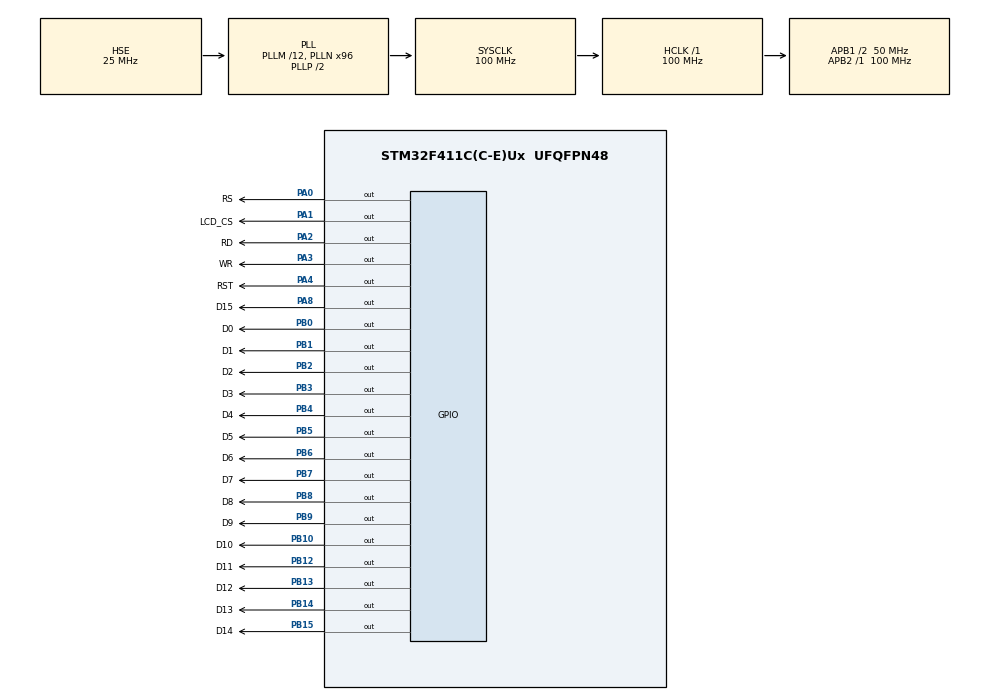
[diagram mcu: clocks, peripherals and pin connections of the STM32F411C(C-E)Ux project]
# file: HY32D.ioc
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Mcu.Family=STM32F4
Mcu.Name=STM32F411C(C-E)Ux
Mcu.Package=UFQFPN48
NVIC.PriorityGroup=NVIC_PRIORITYGROUP_4
PA0-WKUP.GPIO_Label=RS
PA0-WKUP.GPIO_Speed=GPIO_SPEED_FREQ_MEDIUM
PA0-WKUP.Signal=GPIO_Output
PA1.GPIO_Label=LCD_CS
PA1.GPIO_Speed=GPIO_SPEED_FREQ_MEDIUM
PA1.Signal=GPIO_Output
PA13.Mode=Serial_Wire
PA13.Signal=SYS_JTMS-SWDIO
PA14.Mode=Serial_Wire
PA14.Signal=SYS_JTCK-SWCLK
PA2.GPIO_Label=RD
PA2.GPIO_Speed=GPIO_SPEED_FREQ_MEDIUM
PA2.Signal=GPIO_Output
PA3.GPIO_Label=WR
PA3.GPIO_Speed=GPIO_SPEED_FREQ_MEDIUM
PA3.Signal=GPIO_Output
PA4.GPIO_Label=RST
PA4.GPIO_Speed=GPIO_SPEED_FREQ_MEDIUM
PA4.Signal=GPIO_Output
PA8.GPIO_Label=D15
PA8.GPIO_Speed=GPIO_SPEED_FREQ_MEDIUM
PA8.Signal=GPIO_Output
PB0.GPIO_Label=D0
PB0.GPIO_Speed=GPIO_SPEED_FREQ_MEDIUM
PB0.Signal=GPIO_Output
PB1.GPIO_Label=D1
PB1.GPIO_Speed=GPIO_SPEED_FREQ_MEDIUM
PB1.Signal=GPIO_Output
PB10.GPIO_Label=D10
PB10.GPIO_Speed=GPIO_SPEED_FREQ_MEDIUM
PB10.Signal=GPIO_Output
PB12.GPIO_Label=D11
PB12.GPIO_Speed=GPIO_SPEED_FREQ_MEDIUM
PB12.Signal=GPIO_Output
PB13.GPIO_Label=D12
PB13.GPIO_Speed=GPIO_SPEED_FREQ_MEDIUM
PB13.Signal=GPIO_Output
PB14.GPIO_Label=D13
PB14.GPIO_Speed=GPIO_SPEED_FREQ_MEDIUM
PB14.Signal=GPIO_Output
PB15.GPIO_Label=D14
PB15.GPIO_Speed=GPIO_SPEED_FREQ_MEDIUM
PB15.Signal=GPIO_Output
PB2.GPIO_Label=D2
PB2.GPIO_Speed=GPIO_SPEED_FREQ_MEDIUM
PB2.Signal=GPIO_Output
PB3.GPIO_Label=D3
PB3.GPIO_Speed=GPIO_SPEED_FREQ_MEDIUM
PB3.Signal=GPIO_Output
PB4.GPIO_Label=D4
PB4.GPIO_Speed=GPIO_SPEED_FREQ_MEDIUM
PB4.Signal=GPIO_Output
PB5.GPIO_Label=D5
PB5.GPIO_Speed=GPIO_SPEED_FREQ_MEDIUM
PB5.Signal=GPIO_Output
PB6.GPIO_Label=D6
PB6.GPIO_Speed=GPIO_SPEED_FREQ_MEDIUM
PB6.Signal=GPIO_Output
PB7.GPIO_Label=D7
PB7.GPIO_Speed=GPIO_SPEED_FREQ_MEDIUM
PB7.Signal=GPIO_Output
PB8.GPIO_Label=D8
PB8.GPIO_Speed=GPIO_SPEED_FREQ_MEDIUM
PB8.Signal=GPIO_Output
PB9.GPIO_Label=D9
PB9.GPIO_Speed=GPIO_SPEED_FREQ_MEDIUM
PB9.Signal=GPIO_Output
PH0\ -\ OSC_IN.Mode=HSE-External-Oscillator
PH0\ -\ OSC_IN.Signal=RCC_OSC_IN
PH1\ -\ OSC_OUT.Mode=HSE-External-Oscillator
PH1\ -\ OSC_OUT.Signal=RCC_OSC_OUT
ProjectManager.HeapSize=0x200
ProjectManager.StackSize=0x400
ProjectManager.TargetToolchain=EWARM V8
RCC.48MHZClocksFreq_Value=50000000
RCC.AHBFreq_Value=100000000
RCC.APB1CLKDivider=RCC_HCLK_DIV2
RCC.APB1Freq_Value=50000000
RCC.APB1TimFreq_Value=100000000
RCC.APB2Freq_Value=100000000
RCC.APB2TimFreq_Value=100000000
RCC.CortexFreq_Value=100000000
RCC.EnbaleCSS=true
RCC.HCLKFreq_Value=100000000
RCC.HSE_VALUE=25000000
RCC.HSI_VALUE=16000000
RCC.LSE_VALUE=32768
RCC.PLLM=12
RCC.PLLN=96
RCC.PLLSourceVirtual=RCC_PLLSOURCE_HSE
RCC.SYSCLKFreq_VALUE=100000000
RCC.SYSCLKSource=RCC_SYSCLKSOURCE_PLLCLK
RCC.VCOOutputFreq_Value=200000000
board=custom

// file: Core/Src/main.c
/* USER CODE BEGIN Header */
/**
  ******************************************************************************
  * @file           : main.c
  * @brief          : Main program body
  ******************************************************************************
  * @attention
  *
  * Copyright (c) 2023 STMicroelectronics.
  * All rights reserved.
  *
  * This software is licensed under terms that can be found in the LICENSE file
  * in the root directory of this software component.
  * If no LICENSE file comes with this software, it is provided AS-IS.
  *
  ******************************************************************************
  */
/* USER CODE END Header */
#include "main.h"

void SystemClock_Config(void);
static void MX_GPIO_Init(void);
/* USER CODE BEGIN PFP */
void HY32D_Init()
{
  GPIOA->ODR = (1<<RD_Pin);
  GPIOB->ODR = 0x07;
  GPIOA->ODR = (1<<WR_Pin);
  GPIOB->ODR = 0x21;

}
/* USER CODE END PFP */

int main(void)
{

  /* MCU Configuration--------------------------------------------------------*/

  /* Reset of all peripherals, Initializes the Flash interface and the Systick. */
  HAL_Init();

  /* Configure the system clock */
  SystemClock_Config();

  /* Initialize all configured peripherals */
  MX_GPIO_Init();

  /* Infinite loop */
  while (1)
  {

  }
}

void SystemClock_Config(void)
{
  RCC_OscInitTypeDef RCC_OscInitStruct = {0};
  RCC_ClkInitTypeDef RCC_ClkInitStruct = {0};

  /** Configure the main internal regulator output voltage
  */
  __HAL_RCC_PWR_CLK_ENABLE();
  __HAL_PWR_VOLTAGESCALING_CONFIG(PWR_REGULATOR_VOLTAGE_SCALE1);

  /** Initializes the RCC Oscillators according to the specified parameters
  * in the RCC_OscInitTypeDef structure.
  */
  RCC_OscInitStruct.OscillatorType = RCC_OSCILLATORTYPE_HSE;
  RCC_OscInitStruct.HSEState = RCC_HSE_ON;
  RCC_OscInitStruct.PLL.PLLState = RCC_PLL_ON;
  RCC_OscInitStruct.PLL.PLLSource = RCC_PLLSOURCE_HSE;
  RCC_OscInitStruct.PLL.PLLM = 12;
  RCC_OscInitStruct.PLL.PLLN = 96;
  RCC_OscInitStruct.PLL.PLLP = RCC_PLLP_DIV2;
  RCC_OscInitStruct.PLL.PLLQ = 4;
  if (HAL_RCC_OscConfig(&RCC_OscInitStruct) != HAL_OK)
  {
    Error_Handler();
  }

  /** Initializes the CPU, AHB and APB buses clocks
  */
  RCC_ClkInitStruct.ClockType = RCC_CLOCKTYPE_HCLK|RCC_CLOCKTYPE_SYSCLK
                              |RCC_CLOCKTYPE_PCLK1|RCC_CLOCKTYPE_PCLK2;
  RCC_ClkInitStruct.SYSCLKSource = RCC_SYSCLKSOURCE_PLLCLK;
  RCC_ClkInitStruct.AHBCLKDivider = RCC_SYSCLK_DIV1;
  RCC_ClkInitStruct.APB1CLKDivider = RCC_HCLK_DIV2;
  RCC_ClkInitStruct.APB2CLKDivider = RCC_HCLK_DIV1;

  if (HAL_RCC_ClockConfig(&RCC_ClkInitStruct, FLASH_LATENCY_3) != HAL_OK)
  {
    Error_Handler();
  }

  /** Enables the Clock Security System
  */
  HAL_RCC_EnableCSS();
}

static void MX_GPIO_Init(void)
{
  GPIO_InitTypeDef GPIO_InitStruct = {0};

  /* GPIO Ports Clock Enable */
  __HAL_RCC_GPIOH_CLK_ENABLE();
  __HAL_RCC_GPIOA_CLK_ENABLE();
  __HAL_RCC_GPIOB_CLK_ENABLE();

  /*Configure GPIO pin Output Level */
  HAL_GPIO_WritePin(GPIOA, RS_Pin|LCD_CS_Pin|RD_Pin|WR_Pin
                          |RST_Pin|D15_Pin, GPIO_PIN_RESET);

  /*Configure GPIO pin Output Level */
  HAL_GPIO_WritePin(GPIOB, D0_Pin|D1_Pin|D2_Pin|D10_Pin
                          |D11_Pin|D12_Pin|D13_Pin|D14_Pin
                          |D3_Pin|D4_Pin|D5_Pin|D6_Pin
                          |D7_Pin|D8_Pin|D9_Pin, GPIO_PIN_RESET);

  /*Configure GPIO pins : RS_Pin LCD_CS_Pin RD_Pin WR_Pin
                           RST_Pin D15_Pin */
  GPIO_InitStruct.Pin = RS_Pin|LCD_CS_Pin|RD_Pin|WR_Pin
                          |RST_Pin|D15_Pin;
  GPIO_InitStruct.Mode = GPIO_MODE_OUTPUT_PP;
  GPIO_InitStruct.Pull = GPIO_NOPULL;
  GPIO_InitStruct.Speed = GPIO_SPEED_FREQ_MEDIUM;
  HAL_GPIO_Init(GPIOA, &GPIO_InitStruct);

  /*Configure GPIO pins : D0_Pin D1_Pin D2_Pin D10_Pin
                           D11_Pin D12_Pin D13_Pin D14_Pin
                           D3_Pin D4_Pin D5_Pin D6_Pin
                           D7_Pin D8_Pin D9_Pin */
  GPIO_InitStruct.Pin = D0_Pin|D1_Pin|D2_Pin|D10_Pin
                          |D11_Pin|D12_Pin|D13_Pin|D14_Pin
                          |D3_Pin|D4_Pin|D5_Pin|D6_Pin
                          |D7_Pin|D8_Pin|D9_Pin;
  GPIO_InitStruct.Mode = GPIO_MODE_OUTPUT_PP;
  GPIO_InitStruct.Pull = GPIO_NOPULL;
  GPIO_InitStruct.Speed = GPIO_SPEED_FREQ_MEDIUM;
  HAL_GPIO_Init(GPIOB, &GPIO_InitStruct);

}

void Error_Handler(void)
{
  __disable_irq();
  while (1)
  {
  }
}
